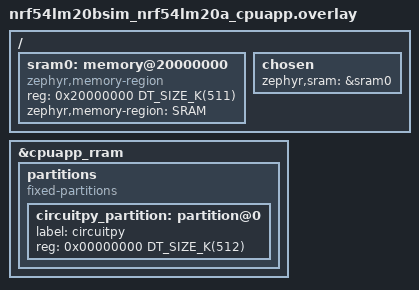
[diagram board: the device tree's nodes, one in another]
/* SPDX-License-Identifier: Apache-2.0 */

/ {
	sram0: memory@20000000 {
		device_type = "memory";
		compatible = "zephyr,memory-region", "mmio-sram";
		reg = <0x20000000 DT_SIZE_K(511)>;
		zephyr,memory-region = "SRAM";
	};

	chosen {
		zephyr,sram = &sram0;
	};
};

&cpuapp_rram {
	/delete-node/ partitions;
	partitions {
		compatible = "fixed-partitions";
		#address-cells = <1>;
		#size-cells = <1>;

		circuitpy_partition: partition@0 {
			label = "circuitpy";
			reg = <0x00000000 DT_SIZE_K(512)>;
		};
	};
};

/* Note: bsim doesn't have USB, so we don't include app.overlay */
